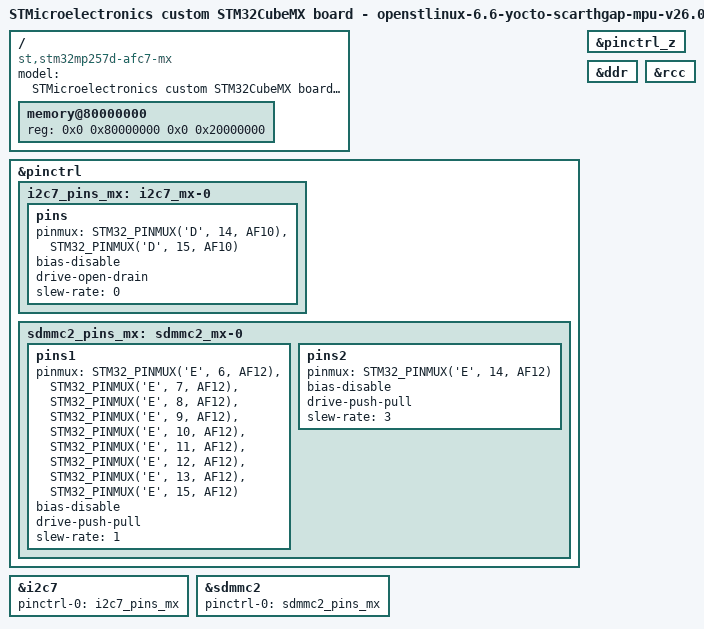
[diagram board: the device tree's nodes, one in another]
// SPDX-License-Identifier: (GPL-2.0-only OR BSD-3-Clause)
/*
 * Copyright (C) 2026, STMicroelectronics - All Rights Reserved
 * Author: STM32CubeMX code generation for STMicroelectronics.
 */

/* For more information on Device Tree configuration, please refer to
 * https://wiki.st.com/stm32mpu/wiki/Category:Device_tree_configuration
 */

/dts-v1/;

#include <dt-bindings/pinctrl/stm32-pinfunc.h>
#include <dt-bindings/clock/stm32mp25-clksrc.h>
#include "stm32mp25-mx.dtsi"

#include "stm32mp257.dtsi"
#include "stm32mp257d-afc7-mx-rcc.dtsi"
#include "stm32mp25xxak-pinctrl.dtsi"
#include "stm32mp25-ddr.dtsi"

/* USER CODE BEGIN includes */
/* USER CODE END includes */

/ {
	model = "STMicroelectronics custom STM32CubeMX board - openstlinux-6.6-yocto-scarthgap-mpu-v26.02.18";
	compatible = "st,stm32mp257d-afc7-mx", "st,stm32mp257";

	memory@80000000 {
		device_type = "memory";
		reg = <0x0 0x80000000 0x0 0x20000000>;

		/* USER CODE BEGIN memory */
		/* USER CODE END memory */
	};

	/* USER CODE BEGIN root */
	/* USER CODE END root */

}; /*root*/

&pinctrl {
	i2c7_pins_mx: i2c7_mx-0 {
		pins {
			pinmux = <STM32_PINMUX('D', 14, AF10)>, /* I2C7_SDA */
					 <STM32_PINMUX('D', 15, AF10)>; /* I2C7_SCL */
			bias-disable;
			drive-open-drain;
			slew-rate = <0>;
		};
	};

	sdmmc2_pins_mx: sdmmc2_mx-0 {
		pins1 {
			pinmux = <STM32_PINMUX('E', 6, AF12)>, /* SDMMC2_D6 */
					 <STM32_PINMUX('E', 7, AF12)>, /* SDMMC2_D7 */
					 <STM32_PINMUX('E', 8, AF12)>, /* SDMMC2_D2 */
					 <STM32_PINMUX('E', 9, AF12)>, /* SDMMC2_D5 */
					 <STM32_PINMUX('E', 10, AF12)>, /* SDMMC2_D4 */
					 <STM32_PINMUX('E', 11, AF12)>, /* SDMMC2_D1 */
					 <STM32_PINMUX('E', 12, AF12)>, /* SDMMC2_D3 */
					 <STM32_PINMUX('E', 13, AF12)>, /* SDMMC2_D0 */
					 <STM32_PINMUX('E', 15, AF12)>; /* SDMMC2_CMD */
			bias-disable;
			drive-push-pull;
			slew-rate = <1>;
		};
		pins2 {
			pinmux = <STM32_PINMUX('E', 14, AF12)>; /* SDMMC2_CK */
			bias-disable;
			drive-push-pull;
			slew-rate = <3>;
		};
	};

	/* USER CODE BEGIN pinctrl */
	/* USER CODE END pinctrl */
};

&pinctrl_z {
	/* USER CODE BEGIN pinctrl_z */
	/* USER CODE END pinctrl_z */
};

&ddr {
	status = "okay";

	/* USER CODE BEGIN ddr */
	/* USER CODE END ddr */
};

&i2c7 {
	pinctrl-names = "default";
	pinctrl-0 = <&i2c7_pins_mx>;
	status = "okay";

	/* USER CODE BEGIN i2c7 */
	/* USER CODE END i2c7 */
};

&rcc {
	status = "okay";

	/* USER CODE BEGIN rcc */
	/* USER CODE END rcc */
};

&sdmmc2 {
	pinctrl-names = "default";
	pinctrl-0 = <&sdmmc2_pins_mx>;
	status = "okay";

	/* USER CODE BEGIN sdmmc2 */
	/* USER CODE END sdmmc2 */
};

/* USER CODE BEGIN addons */
/* USER CODE END addons */

